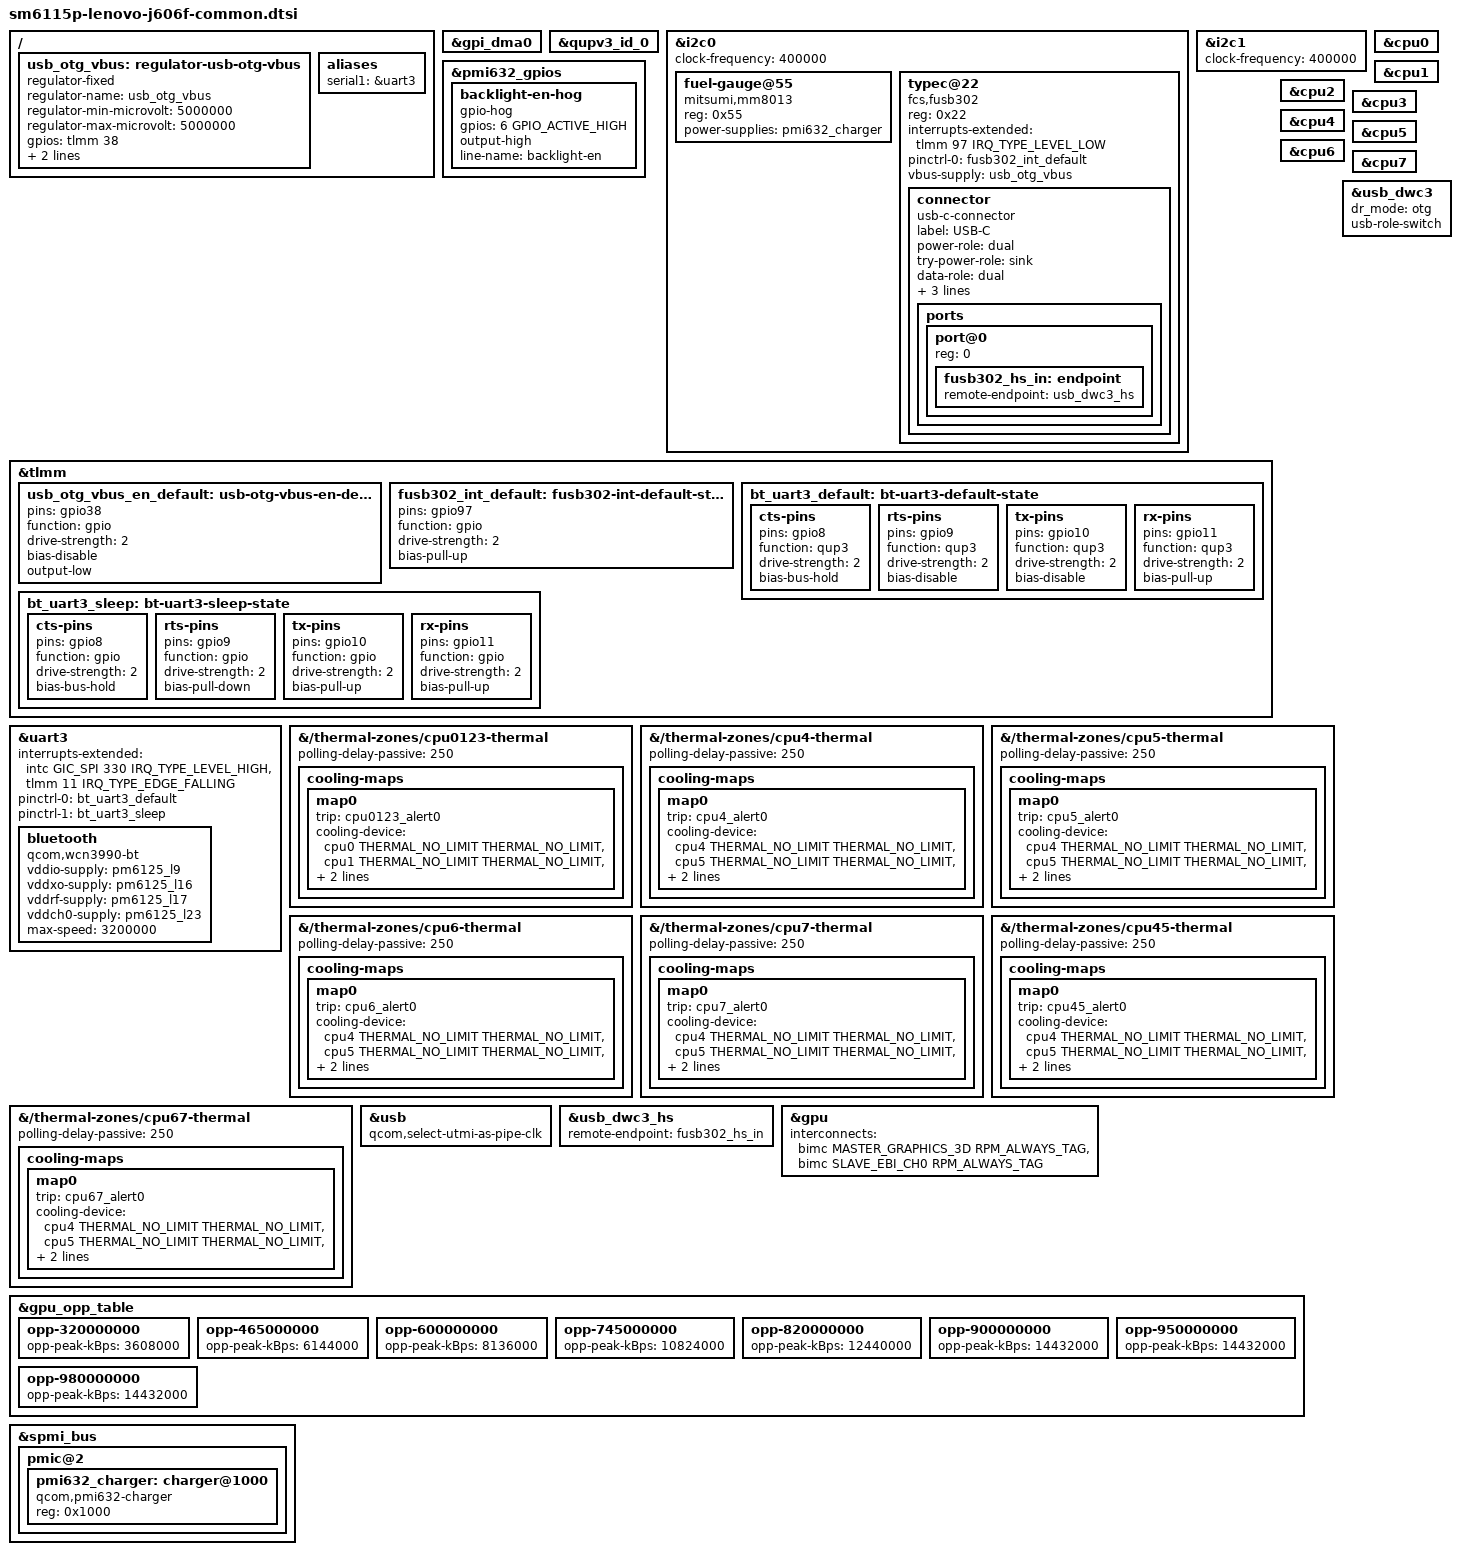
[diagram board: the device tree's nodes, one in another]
// SPDX-License-Identifier: (GPL-2.0+ OR BSD-3-Clause)
/*
 * Lenovo Tab P11 (TB-J606F): board parts shared by both panel SKUs
 * (BOE + Himax HX83102P TDDI, BOE + Novatek NT36523W). Included after
 * sm6115p-lenovo-j606f.dts by the per-SKU dts. Values come from the stock DT of
 * TB-J606F_S120184_210520_ROW (see notes/stock_dt/).
 */

#include "pmi632.dtsi"
/* Lenovo ABL applies the stock dtbo unconditionally unless dtbo is erased, see the dtsi */
#include "sm6115p-lenovo-j606f-abl-sink.dtsi"

/ {
	usb_otg_vbus: regulator-usb-otg-vbus {
		compatible = "regulator-fixed";
		regulator-name = "usb_otg_vbus";
		regulator-min-microvolt = <5000000>;
		regulator-max-microvolt = <5000000>;
		gpios = <&tlmm 38 GPIO_ACTIVE_HIGH>;
		enable-active-high;
		pinctrl-0 = <&usb_otg_vbus_en_default>;
		pinctrl-names = "default";
	};

	aliases {
		serial1 = &uart3;
	};
};

&gpi_dma0 {
	status = "okay";
};

&qupv3_id_0 {
	status = "okay";
};

&i2c0 {
	clock-frequency = <400000>;
	status = "okay";

	fuel-gauge@55 {
		compatible = "mitsumi,mm8013";
		reg = <0x55>;
		power-supplies = <&pmi632_charger>;
	};
};

&i2c1 {
	clock-frequency = <400000>;
	status = "okay";
};

&pmi632_gpios {
	/* SGM37604A LED driver enable (stock: qcom,platform-bklight-en-gpio) */
	backlight-en-hog {
		gpio-hog;
		gpios = <6 GPIO_ACTIVE_HIGH>;
		output-high;
		line-name = "backlight-en";
	};
};

&tlmm {
	/* stock dock_pogo usb_vbus: enable of the external 5 V OTG boost */
	usb_otg_vbus_en_default: usb-otg-vbus-en-default-state {
		pins = "gpio38";
		function = "gpio";
		drive-strength = <2>;
		bias-disable;
		output-low;
	};

	/* stock fairchild_int_gpio */
	fusb302_int_default: fusb302-int-default-state {
		pins = "gpio97";
		function = "gpio";
		drive-strength = <2>;
		bias-pull-up;
	};

	/* WCN3990 BT UART (QUP SE3), pins from stock qupv3_se3_4uart */
	bt_uart3_default: bt-uart3-default-state {
		cts-pins {
			pins = "gpio8";
			function = "qup3";
			drive-strength = <2>;
			bias-bus-hold;
		};

		rts-pins {
			pins = "gpio9";
			function = "qup3";
			drive-strength = <2>;
			bias-disable;
		};

		tx-pins {
			pins = "gpio10";
			function = "qup3";
			drive-strength = <2>;
			bias-disable;
		};

		rx-pins {
			pins = "gpio11";
			function = "qup3";
			drive-strength = <2>;
			bias-pull-up;
		};
	};

	bt_uart3_sleep: bt-uart3-sleep-state {
		cts-pins {
			pins = "gpio8";
			function = "gpio";
			drive-strength = <2>;
			bias-bus-hold;
		};

		rts-pins {
			pins = "gpio9";
			function = "gpio";
			drive-strength = <2>;
			bias-pull-down;
		};

		tx-pins {
			pins = "gpio10";
			function = "gpio";
			drive-strength = <2>;
			bias-pull-up;
		};

		rx-pins {
			pins = "gpio11";
			function = "gpio";
			drive-strength = <2>;
			bias-pull-up;
		};
	};
};

&uart3 {
	interrupts-extended = <&intc GIC_SPI 330 IRQ_TYPE_LEVEL_HIGH>,
			      <&tlmm 11 IRQ_TYPE_EDGE_FALLING>;
	pinctrl-0 = <&bt_uart3_default>;
	pinctrl-1 = <&bt_uart3_sleep>;
	pinctrl-names = "default", "sleep";
	status = "okay";

	bluetooth {
		compatible = "qcom,wcn3990-bt";
		/* stock bt_wcn3990: io = L9, core = L17, pa = L23, xtal = L16 */
		vddio-supply = <&pm6125_l9>;
		vddxo-supply = <&pm6125_l16>;
		vddrf-supply = <&pm6125_l17>;
		vddch0-supply = <&pm6125_l23>;
		max-speed = <3200000>;
	};
};

/*
 * CPU thermal throttling: sm6115.dtsi has passive trips on the CPU zones but no
 * cooling devices; without these the kernel never lowers CPU clocks on overheat.
 */
&cpu0 {
	#cooling-cells = <2>;
};

&cpu1 {
	#cooling-cells = <2>;
};

&cpu2 {
	#cooling-cells = <2>;
};

&cpu3 {
	#cooling-cells = <2>;
};

&cpu4 {
	#cooling-cells = <2>;
};

&cpu5 {
	#cooling-cells = <2>;
};

&cpu6 {
	#cooling-cells = <2>;
};

&cpu7 {
	#cooling-cells = <2>;
};

&{/thermal-zones/cpu0123-thermal} {
	polling-delay-passive = <250>;

	cooling-maps {
		map0 {
			trip = <&cpu0123_alert0>;
			cooling-device = <&cpu0 THERMAL_NO_LIMIT THERMAL_NO_LIMIT>,
						 <&cpu1 THERMAL_NO_LIMIT THERMAL_NO_LIMIT>,
						 <&cpu2 THERMAL_NO_LIMIT THERMAL_NO_LIMIT>,
						 <&cpu3 THERMAL_NO_LIMIT THERMAL_NO_LIMIT>;
		};
	};
};

&{/thermal-zones/cpu4-thermal} {
	polling-delay-passive = <250>;

	cooling-maps {
		map0 {
			trip = <&cpu4_alert0>;
			cooling-device = <&cpu4 THERMAL_NO_LIMIT THERMAL_NO_LIMIT>,
						 <&cpu5 THERMAL_NO_LIMIT THERMAL_NO_LIMIT>,
						 <&cpu6 THERMAL_NO_LIMIT THERMAL_NO_LIMIT>,
						 <&cpu7 THERMAL_NO_LIMIT THERMAL_NO_LIMIT>;
		};
	};
};

&{/thermal-zones/cpu5-thermal} {
	polling-delay-passive = <250>;

	cooling-maps {
		map0 {
			trip = <&cpu5_alert0>;
			cooling-device = <&cpu4 THERMAL_NO_LIMIT THERMAL_NO_LIMIT>,
						 <&cpu5 THERMAL_NO_LIMIT THERMAL_NO_LIMIT>,
						 <&cpu6 THERMAL_NO_LIMIT THERMAL_NO_LIMIT>,
						 <&cpu7 THERMAL_NO_LIMIT THERMAL_NO_LIMIT>;
		};
	};
};

&{/thermal-zones/cpu6-thermal} {
	polling-delay-passive = <250>;

	cooling-maps {
		map0 {
			trip = <&cpu6_alert0>;
			cooling-device = <&cpu4 THERMAL_NO_LIMIT THERMAL_NO_LIMIT>,
						 <&cpu5 THERMAL_NO_LIMIT THERMAL_NO_LIMIT>,
						 <&cpu6 THERMAL_NO_LIMIT THERMAL_NO_LIMIT>,
						 <&cpu7 THERMAL_NO_LIMIT THERMAL_NO_LIMIT>;
		};
	};
};

&{/thermal-zones/cpu7-thermal} {
	polling-delay-passive = <250>;

	cooling-maps {
		map0 {
			trip = <&cpu7_alert0>;
			cooling-device = <&cpu4 THERMAL_NO_LIMIT THERMAL_NO_LIMIT>,
						 <&cpu5 THERMAL_NO_LIMIT THERMAL_NO_LIMIT>,
						 <&cpu6 THERMAL_NO_LIMIT THERMAL_NO_LIMIT>,
						 <&cpu7 THERMAL_NO_LIMIT THERMAL_NO_LIMIT>;
		};
	};
};

&{/thermal-zones/cpu45-thermal} {
	polling-delay-passive = <250>;

	cooling-maps {
		map0 {
			trip = <&cpu45_alert0>;
			cooling-device = <&cpu4 THERMAL_NO_LIMIT THERMAL_NO_LIMIT>,
						 <&cpu5 THERMAL_NO_LIMIT THERMAL_NO_LIMIT>,
						 <&cpu6 THERMAL_NO_LIMIT THERMAL_NO_LIMIT>,
						 <&cpu7 THERMAL_NO_LIMIT THERMAL_NO_LIMIT>;
		};
	};
};

&{/thermal-zones/cpu67-thermal} {
	polling-delay-passive = <250>;

	cooling-maps {
		map0 {
			trip = <&cpu67_alert0>;
			cooling-device = <&cpu4 THERMAL_NO_LIMIT THERMAL_NO_LIMIT>,
						 <&cpu5 THERMAL_NO_LIMIT THERMAL_NO_LIMIT>,
						 <&cpu6 THERMAL_NO_LIMIT THERMAL_NO_LIMIT>,
						 <&cpu7 THERMAL_NO_LIMIT THERMAL_NO_LIMIT>;
		};
	};
};

/*
 * USB runs on the HS PHY only (the base DTS drops the QMP PHY); without this the
 * pipe clock is never selected and dwc3 fails with "failed to enable ep0out"
 * unless ABL fastboot already configured the controller.
 */
&usb {
	qcom,select-utmi-as-pipe-clk;
};

/*
 * USB-C OTG. On this board the PMI632 Type-C block is strapped to micro-USB mode
 * (TYPEC_U_USB_CFG 0x1570 = 0x03, the stock qpnp-smb5 reads the same bit), the CC lines
 * go to an FUSB302B (I2C0 0x22, Device ID 0x91, INT_N on gpio97, stock "qcom,fusb302").
 * VBUS for sinks is NOT the PMI632 OTG boost: the stock fusb302 driver switches an
 * external 5 V boost with gpio38 (dock_pogo "usb_vbus", pogo.c usb_vbus_ctl). TCPM turns
 * it on only after it saw Rd on CC. HS only: the base dts has no QMP PHY. No USB PD.
 */
&i2c0 {
	typec@22 {
		compatible = "fcs,fusb302";
		reg = <0x22>;
		interrupts-extended = <&tlmm 97 IRQ_TYPE_LEVEL_LOW>;
		pinctrl-0 = <&fusb302_int_default>;
		pinctrl-names = "default";
		vbus-supply = <&usb_otg_vbus>;

		connector {
			compatible = "usb-c-connector";
			label = "USB-C";

			power-role = "dual";
			try-power-role = "sink";
			data-role = "dual";
			self-powered;

			typec-power-opmode = "default";
			pd-disable;

			ports {
				#address-cells = <1>;
				#size-cells = <0>;

				port@0 {
					reg = <0>;

					fusb302_hs_in: endpoint {
						remote-endpoint = <&usb_dwc3_hs>;
					};
				};
			};
		};
	};
};

&usb_dwc3 {
	/* the base dts forces peripheral mode and drops the role switch */
	dr_mode = "otg";
	usb-role-switch;
};

&usb_dwc3_hs {
	remote-endpoint = <&fusb302_hs_in>;
};

/*
 * GPU memory bandwidth: sm6115.dtsi gives the Adreno no interconnect path, so it never
 * votes for DDR bandwidth and the BIMC stays at whatever other masters asked for (glmark2
 * 277, vkmark 87, vkmark "clear" 130 fps at 800x600). Peak values per GPU OPP from the
 * stock kgsl table (qcom,msm-bus vectors ib, bus-freq index per gpu-pwrlevel).
 */
&gpu {
	interconnects = <&bimc MASTER_GRAPHICS_3D RPM_ALWAYS_TAG
			 &bimc SLAVE_EBI_CH0 RPM_ALWAYS_TAG>;
	interconnect-names = "gfx-mem";
};

&gpu_opp_table {
	opp-320000000 {
		opp-peak-kBps = <3608000>;
	};

	opp-465000000 {
		opp-peak-kBps = <6144000>;
	};

	opp-600000000 {
		opp-peak-kBps = <8136000>;
	};

	opp-745000000 {
		opp-peak-kBps = <10824000>;
	};

	opp-820000000 {
		opp-peak-kBps = <12440000>;
	};

	opp-900000000 {
		opp-peak-kBps = <14432000>;
	};

	opp-950000000 {
		opp-peak-kBps = <14432000>;
	};

	opp-980000000 {
		opp-peak-kBps = <14432000>;
	};
};

/* PMI632 SMB5 charger, read-only status driver for now */
&spmi_bus {
	pmic@2 {
		pmi632_charger: charger@1000 {
			compatible = "qcom,pmi632-charger";
			reg = <0x1000>;
		};
	};
};
